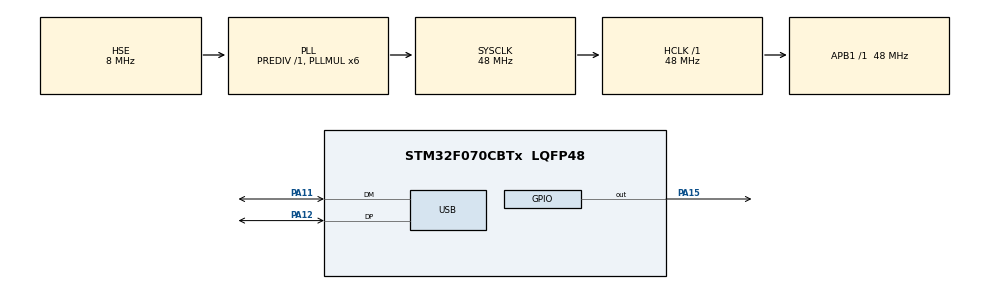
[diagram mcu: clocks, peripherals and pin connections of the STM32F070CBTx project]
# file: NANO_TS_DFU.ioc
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Mcu.Family=STM32F0
Mcu.Name=STM32F070CBTx
Mcu.Package=LQFP48
NVIC.USB_IRQn=true\:0\:0\:false\:false\:true\:false\:true\:true
PA11.Mode=Device
PA11.Signal=USB_DM
PA12.Mode=Device
PA12.Signal=USB_DP
PA15.Signal=GPIO_Output
PF0-OSC_IN.Mode=HSE-External-Oscillator
PF0-OSC_IN.Signal=RCC_OSC_IN
PF1-OSC_OUT.Mode=HSE-External-Oscillator
PF1-OSC_OUT.Signal=RCC_OSC_OUT
ProjectManager.HeapSize=0x200
ProjectManager.StackSize=0x400
ProjectManager.TargetToolchain=STM32CubeIDE
RCC.AHBFreq_Value=48000000
RCC.APB1Freq_Value=48000000
RCC.APB1TimFreq_Value=48000000
RCC.HCLKFreq_Value=48000000
RCC.PLLMUL=RCC_PLL_MUL6
RCC.SYSCLKFreq_VALUE=48000000
RCC.SYSCLKSource=RCC_SYSCLKSOURCE_PLLCLK
USB_DEVICE.CLASS_NAME_FS=DFU
USB_DEVICE.MANUFACTURER_STRING=NANO TS
USB_DEVICE.PID_DFU_FS=0x2b70
USB_DEVICE.PRODUCT_STRING_DFU_FS=NANO TS DFU
USB_DEVICE.USBD_DFU_APP_DEFAULT_ADD=0x08020000
USB_DEVICE.USBD_DFU_MEDIA=@Internal Flash /0x08000000/01*0128Ka,01*0128Kg,01*0128Kg,01*0128Kg,01*0128Kg,01*0128Kg,01*0128Kg,01*0128Kg
USB_DEVICE.USBD_DFU_XFER_SIZE=4096
USB_DEVICE.VID=0x2b7f
USB_DEVICE.VirtualMode=Dfu
USB_DEVICE.VirtualModeFS=Dfu_FS
VP_USB_DEVICE_VS_USB_DEVICE_DFU_FS.Mode=DFU_FS
board=custom

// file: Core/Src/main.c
/* USER CODE BEGIN Header */
/**
  ******************************************************************************
  * @file           : main.c
  * @brief          : Main program body
  ******************************************************************************
  * @attention
  *
  * Copyright (c) 2024 STMicroelectronics.
  * All rights reserved.
  *
  * This software is licensed under terms that can be found in the LICENSE file
  * in the root directory of this software component.
  * If no LICENSE file comes with this software, it is provided AS-IS.
  *
  ******************************************************************************
  */
/* USER CODE END Header */
#include "main.h"
#include "usb_device.h"

void SystemClock_Config(void);
static void MX_GPIO_Init(void);

int main(void)
{

  /* MCU Configuration--------------------------------------------------------*/

  /* Reset of all peripherals, Initializes the Flash interface and the Systick. */
  HAL_Init();

  /* Configure the system clock */
  SystemClock_Config();

  /* Initialize all configured peripherals */
  MX_GPIO_Init();
  MX_USB_DEVICE_Init();
  /* USER CODE BEGIN 2 */
  HAL_GPIO_WritePin(GPIOA, GPIO_PIN_15, GPIO_PIN_RESET);
  /* USER CODE END 2 */

  /* Infinite loop */
  while (1)
  {

  }
}

void SystemClock_Config(void)
{
  RCC_OscInitTypeDef RCC_OscInitStruct = {0};
  RCC_ClkInitTypeDef RCC_ClkInitStruct = {0};
  RCC_PeriphCLKInitTypeDef PeriphClkInit = {0};

  /** Initializes the RCC Oscillators according to the specified parameters
  * in the RCC_OscInitTypeDef structure.
  */
  RCC_OscInitStruct.OscillatorType = RCC_OSCILLATORTYPE_HSE;
  RCC_OscInitStruct.HSEState = RCC_HSE_ON;
  RCC_OscInitStruct.PLL.PLLState = RCC_PLL_ON;
  RCC_OscInitStruct.PLL.PLLSource = RCC_PLLSOURCE_HSE;
  RCC_OscInitStruct.PLL.PLLMUL = RCC_PLL_MUL6;
  RCC_OscInitStruct.PLL.PREDIV = RCC_PREDIV_DIV1;
  if (HAL_RCC_OscConfig(&RCC_OscInitStruct) != HAL_OK)
  {
    Error_Handler();
  }

  /** Initializes the CPU, AHB and APB buses clocks
  */
  RCC_ClkInitStruct.ClockType = RCC_CLOCKTYPE_HCLK|RCC_CLOCKTYPE_SYSCLK
                              |RCC_CLOCKTYPE_PCLK1;
  RCC_ClkInitStruct.SYSCLKSource = RCC_SYSCLKSOURCE_PLLCLK;
  RCC_ClkInitStruct.AHBCLKDivider = RCC_SYSCLK_DIV1;
  RCC_ClkInitStruct.APB1CLKDivider = RCC_HCLK_DIV1;

  if (HAL_RCC_ClockConfig(&RCC_ClkInitStruct, FLASH_LATENCY_1) != HAL_OK)
  {
    Error_Handler();
  }
  PeriphClkInit.PeriphClockSelection = RCC_PERIPHCLK_USB;
  PeriphClkInit.UsbClockSelection = RCC_USBCLKSOURCE_PLL;

  if (HAL_RCCEx_PeriphCLKConfig(&PeriphClkInit) != HAL_OK)
  {
    Error_Handler();
  }
}

static void MX_GPIO_Init(void)
{
  GPIO_InitTypeDef GPIO_InitStruct = {0};

  /* GPIO Ports Clock Enable */
  __HAL_RCC_GPIOF_CLK_ENABLE();
  __HAL_RCC_GPIOA_CLK_ENABLE();

  /*Configure GPIO pin Output Level */
  HAL_GPIO_WritePin(GPIOA, GPIO_PIN_15, GPIO_PIN_RESET);

  /*Configure GPIO pin : PA15 */
  GPIO_InitStruct.Pin = GPIO_PIN_15;
  GPIO_InitStruct.Mode = GPIO_MODE_OUTPUT_PP;
  GPIO_InitStruct.Pull = GPIO_NOPULL;
  GPIO_InitStruct.Speed = GPIO_SPEED_FREQ_LOW;
  HAL_GPIO_Init(GPIOA, &GPIO_InitStruct);

}

void Error_Handler(void)
{
  __disable_irq();
  while (1)
  {
  }
}
